# CTRL_MMR0_CFG0 register map
Vendor: Texas Instruments
Registers are 32-bit, read-write, reset 0x0 unless marked. A register's access mark holds for its fields unless they carry their own. Offsets are as the file gives them; [hi:lo] are bit positions; {n}, {i} and the like mark numbered series; 'fields as' and 'values as' point back to an identical list.

## CTRL_MMR0_CFG0 (part 5 of 9)
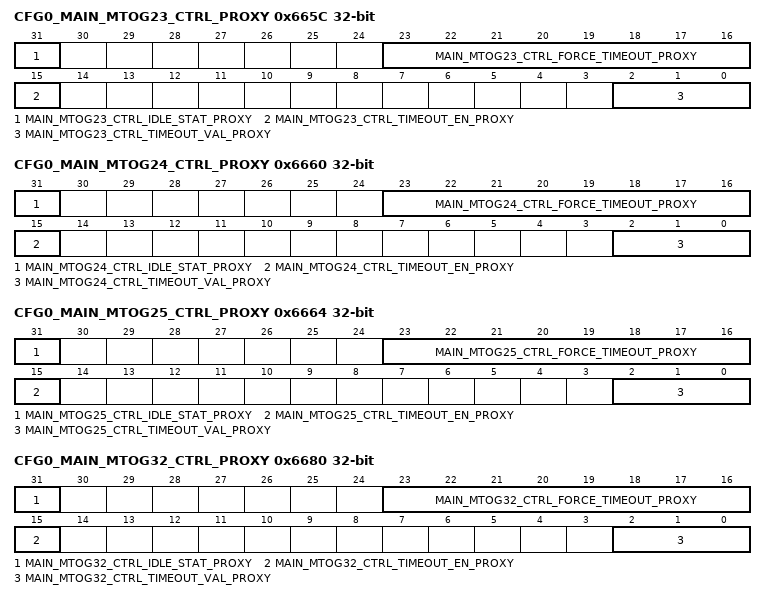
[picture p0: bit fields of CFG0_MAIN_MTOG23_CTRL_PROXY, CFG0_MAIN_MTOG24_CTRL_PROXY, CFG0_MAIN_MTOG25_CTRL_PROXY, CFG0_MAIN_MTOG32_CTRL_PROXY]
0x665C CFG0_MAIN_MTOG23_CTRL_PROXY access per field — Controls timeout operation of write transactions from the MAIN R5 Clstr1 Core 1 VBUSM Memory master port
  [31] MAIN_MTOG23_CTRL_IDLE_STAT_PROXY ro — Idle statusWhen high, indicates MTOG23 is idle.
  [23:16] MAIN_MTOG23_CTRL_FORCE_TIMEOUT_PROXY rw — Force TimeoutForces a flush of the interface transactions. This bitfield is only relevant if timeout_en=1. After forcing a timeout by writing the encoded value, the force_timeout and timeout_en bitfields must be cleared to clear the timeout before re-enabling the gasket. 8'h95 - Force a gasket timeoutAll others - Normal operation
  [15] MAIN_MTOG23_CTRL_TIMEOUT_EN_PROXY rw — Timeout Enable 1'b0 - Disable the gasket. Clear the interrupt and reset the counter 1'b1 - Enable the timeout gasket functions
  [2:0] MAIN_MTOG23_CTRL_TIMEOUT_VAL_PROXY rw — Gasket Timeout ValueSelects the number of clock cycles before the interface is considered to have timed out Field values (Others are reserved): 3'b000 - 1024 clock cycles 3'b001 - 4096 clock cycles 3'b010 - 16,384 clock cycles 3'b011 - 65,536 clock cycles 3'b100 - 262,144 clock cycles 3'b101 - 1,048,576 clock cycles 3'b110 - 2,097,152 clock cycles 3'b111 - 4,194,303 clock cycles
0x6660 CFG0_MAIN_MTOG24_CTRL_PROXY access per field — Controls timeout operation of real time transactions from High Speed IO masters
  [31] MAIN_MTOG24_CTRL_IDLE_STAT_PROXY ro — Idle statusWhen high, indicates MTOG24 is idle.
  [23:16] MAIN_MTOG24_CTRL_FORCE_TIMEOUT_PROXY rw — Force TimeoutForces a flush of the interface transactions. This bitfield is only relevant if timeout_en=1. After forcing a timeout by writing the encoded value, the force_timeout and timeout_en bitfields must be cleared to clear the timeout before re-enabling the gasket. 8'h95 - Force a gasket timeoutAll others - Normal operation
  [15] MAIN_MTOG24_CTRL_TIMEOUT_EN_PROXY rw — Timeout Enable 1'b0 - Disable the gasket. Clear the interrupt and reset the counter 1'b1 - Enable the timeout gasket functions
  [2:0] MAIN_MTOG24_CTRL_TIMEOUT_VAL_PROXY rw — Gasket Timeout ValueSelects the number of clock cycles before the interface is considered to have timed out Field values (Others are reserved): 3'b000 - 1024 clock cycles 3'b001 - 4096 clock cycles 3'b010 - 16,384 clock cycles 3'b011 - 65,536 clock cycles 3'b100 - 262,144 clock cycles 3'b101 - 1,048,576 clock cycles 3'b110 - 2,097,152 clock cycles 3'b111 - 4,194,303 clock cycles
0x6664 CFG0_MAIN_MTOG25_CTRL_PROXY access per field — Controls timeout operation of non-real time transactions from High Speed IO masters
  [31] MAIN_MTOG25_CTRL_IDLE_STAT_PROXY ro — Idle statusWhen high, indicates MTOG25 is idle.
  [23:16] MAIN_MTOG25_CTRL_FORCE_TIMEOUT_PROXY rw — Force TimeoutForces a flush of the interface transactions. This bitfield is only relevant if timeout_en=1. After forcing a timeout by writing the encoded value, the force_timeout and timeout_en bitfields must be cleared to clear the timeout before re-enabling the gasket. 8'h95 - Force a gasket timeoutAll others - Normal operation
  [15] MAIN_MTOG25_CTRL_TIMEOUT_EN_PROXY rw — Timeout Enable 1'b0 - Disable the gasket. Clear the interrupt and reset the counter 1'b1 - Enable the timeout gasket functions
  [2:0] MAIN_MTOG25_CTRL_TIMEOUT_VAL_PROXY rw — Gasket Timeout ValueSelects the number of clock cycles before the interface is considered to have timed out Field values (Others are reserved): 3'b000 - 1024 clock cycles 3'b001 - 4096 clock cycles 3'b010 - 16,384 clock cycles 3'b011 - 65,536 clock cycles 3'b100 - 262,144 clock cycles 3'b101 - 1,048,576 clock cycles 3'b110 - 2,097,152 clock cycles 3'b111 - 4,194,303 clock cycles
0x6680 CFG0_MAIN_MTOG32_CTRL_PROXY access per field — Controls timeout operation of Accelerator Cluster ASIL-B master accesses to MSMC (L2) SRAM
  [31] MAIN_MTOG32_CTRL_IDLE_STAT_PROXY ro — Idle statusWhen high, indicates MTOG32 is idle.
  [23:16] MAIN_MTOG32_CTRL_FORCE_TIMEOUT_PROXY rw — Force TimeoutForces a flush of the interface transactions. This bitfield is only relevant if timeout_en=1. After forcing a timeout by writing the encoded value, the force_timeout and timeout_en bitfields must be cleared to clear the timeout before re-enabling the gasket. 8'h95 - Force a gasket timeoutAll others - Normal operation
  [15] MAIN_MTOG32_CTRL_TIMEOUT_EN_PROXY rw — Timeout Enable 1'b0 - Disable the gasket. Clear the interrupt and reset the counter 1'b1 - Enable the timeout gasket functions
  [2:0] MAIN_MTOG32_CTRL_TIMEOUT_VAL_PROXY rw — Gasket Timeout ValueSelects the number of clock cycles before the interface is considered to have timed out Field values (Others are reserved): 3'b000 - 1024 clock cycles 3'b001 - 4096 clock cycles 3'b010 - 16,384 clock cycles 3'b011 - 65,536 clock cycles 3'b100 - 262,144 clock cycles 3'b101 - 1,048,576 clock cycles 3'b110 - 2,097,152 clock cycles 3'b111 - 4,194,303 clock cycles
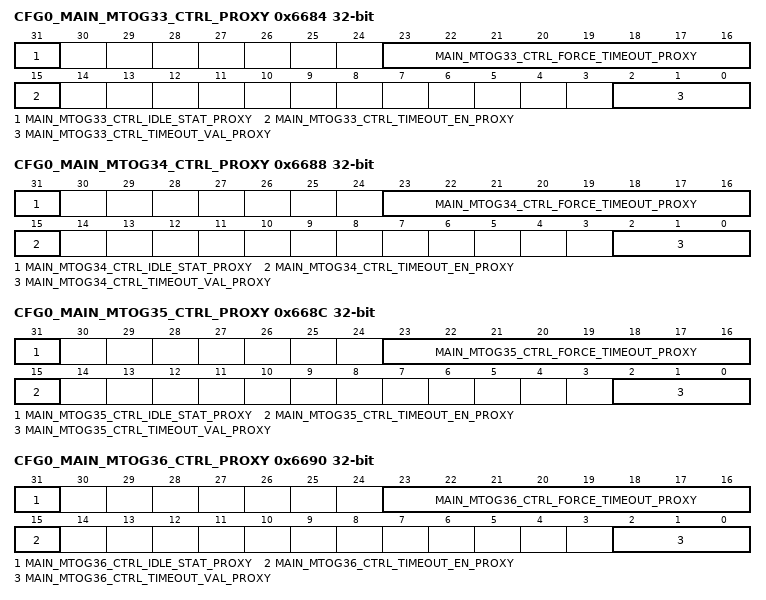
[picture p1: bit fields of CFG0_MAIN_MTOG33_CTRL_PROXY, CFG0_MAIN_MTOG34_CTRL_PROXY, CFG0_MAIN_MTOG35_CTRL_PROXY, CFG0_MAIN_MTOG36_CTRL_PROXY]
0x6684 CFG0_MAIN_MTOG33_CTRL_PROXY access per field — Controls timeout operation of Accelerator Cluster QueueManager master accesses to MSMC (L2) SRAM
  [31] MAIN_MTOG33_CTRL_IDLE_STAT_PROXY ro — Idle statusWhen high, indicates MTOG33 is idle.
  [23:16] MAIN_MTOG33_CTRL_FORCE_TIMEOUT_PROXY rw — Force TimeoutForces a flush of the interface transactions. This bitfield is only relevant if timeout_en=1. After forcing a timeout by writing the encoded value, the force_timeout and timeout_en bitfields must be cleared to clear the timeout before re-enabling the gasket. 8'h95 - Force a gasket timeoutAll others - Normal operation
  [15] MAIN_MTOG33_CTRL_TIMEOUT_EN_PROXY rw — Timeout Enable 1'b0 - Disable the gasket. Clear the interrupt and reset the counter 1'b1 - Enable the timeout gasket functions
  [2:0] MAIN_MTOG33_CTRL_TIMEOUT_VAL_PROXY rw — Gasket Timeout ValueSelects the number of clock cycles before the interface is considered to have timed out Field values (Others are reserved): 3'b000 - 1024 clock cycles 3'b001 - 4096 clock cycles 3'b010 - 16,384 clock cycles 3'b011 - 65,536 clock cycles 3'b100 - 262,144 clock cycles 3'b101 - 1,048,576 clock cycles 3'b110 - 2,097,152 clock cycles 3'b111 - 4,194,303 clock cycles
0x6688 CFG0_MAIN_MTOG34_CTRL_PROXY access per field — Controls timeout operation of Accelerator Cluster ASIL-B master accesses to DDR for OrderIDs 0-4
  [31] MAIN_MTOG34_CTRL_IDLE_STAT_PROXY ro — Idle statusWhen high, indicates MTOG34 is idle.
  [23:16] MAIN_MTOG34_CTRL_FORCE_TIMEOUT_PROXY rw — Force TimeoutForces a flush of the interface transactions. This bitfield is only relevant if timeout_en=1. After forcing a timeout by writing the encoded value, the force_timeout and timeout_en bitfields must be cleared to clear the timeout before re-enabling the gasket. 8'h95 - Force a gasket timeoutAll others - Normal operation
  [15] MAIN_MTOG34_CTRL_TIMEOUT_EN_PROXY rw — Timeout Enable 1'b0 - Disable the gasket. Clear the interrupt and reset the counter 1'b1 - Enable the timeout gasket functions
  [2:0] MAIN_MTOG34_CTRL_TIMEOUT_VAL_PROXY rw — Gasket Timeout ValueSelects the number of clock cycles before the interface is considered to have timed out Field values (Others are reserved): 3'b000 - 1024 clock cycles 3'b001 - 4096 clock cycles 3'b010 - 16,384 clock cycles 3'b011 - 65,536 clock cycles 3'b100 - 262,144 clock cycles 3'b101 - 1,048,576 clock cycles 3'b110 - 2,097,152 clock cycles 3'b111 - 4,194,303 clock cycles
0x668C CFG0_MAIN_MTOG35_CTRL_PROXY access per field — Controls timeout operation of Accelerator Cluster QueueManager master accesses to DDR fro OrderIDs 0-4
  [31] MAIN_MTOG35_CTRL_IDLE_STAT_PROXY ro — Idle statusWhen high, indicates MTOG35 is idle.
  [23:16] MAIN_MTOG35_CTRL_FORCE_TIMEOUT_PROXY rw — Force TimeoutForces a flush of the interface transactions. This bitfield is only relevant if timeout_en=1. After forcing a timeout by writing the encoded value, the force_timeout and timeout_en bitfields must be cleared to clear the timeout before re-enabling the gasket. 8'h95 - Force a gasket timeoutAll others - Normal operation
  [15] MAIN_MTOG35_CTRL_TIMEOUT_EN_PROXY rw — Timeout Enable 1'b0 - Disable the gasket. Clear the interrupt and reset the counter 1'b1 - Enable the timeout gasket functions
  [2:0] MAIN_MTOG35_CTRL_TIMEOUT_VAL_PROXY rw — Gasket Timeout ValueSelects the number of clock cycles before the interface is considered to have timed out Field values (Others are reserved): 3'b000 - 1024 clock cycles 3'b001 - 4096 clock cycles 3'b010 - 16,384 clock cycles 3'b011 - 65,536 clock cycles 3'b100 - 262,144 clock cycles 3'b101 - 1,048,576 clock cycles 3'b110 - 2,097,152 clock cycles 3'b111 - 4,194,303 clock cycles
0x6690 CFG0_MAIN_MTOG36_CTRL_PROXY access per field — Controls timeout operation of Accelerator Cluster ASIL-B master accesses to DDR for OrderIDs 5-9
  [31] MAIN_MTOG36_CTRL_IDLE_STAT_PROXY ro — Idle statusWhen high, indicates MTOG36 is idle.
  [23:16] MAIN_MTOG36_CTRL_FORCE_TIMEOUT_PROXY rw — Force TimeoutForces a flush of the interface transactions. This bitfield is only relevant if timeout_en=1. After forcing a timeout by writing the encoded value, the force_timeout and timeout_en bitfields must be cleared to clear the timeout before re-enabling the gasket. 8'h95 - Force a gasket timeoutAll others - Normal operation
  [15] MAIN_MTOG36_CTRL_TIMEOUT_EN_PROXY rw — Timeout Enable 1'b0 - Disable the gasket. Clear the interrupt and reset the counter 1'b1 - Enable the timeout gasket functions
  [2:0] MAIN_MTOG36_CTRL_TIMEOUT_VAL_PROXY rw — Gasket Timeout ValueSelects the number of clock cycles before the interface is considered to have timed out Field values (Others are reserved): 3'b000 - 1024 clock cycles 3'b001 - 4096 clock cycles 3'b010 - 16,384 clock cycles 3'b011 - 65,536 clock cycles 3'b100 - 262,144 clock cycles 3'b101 - 1,048,576 clock cycles 3'b110 - 2,097,152 clock cycles 3'b111 - 4,194,303 clock cycles
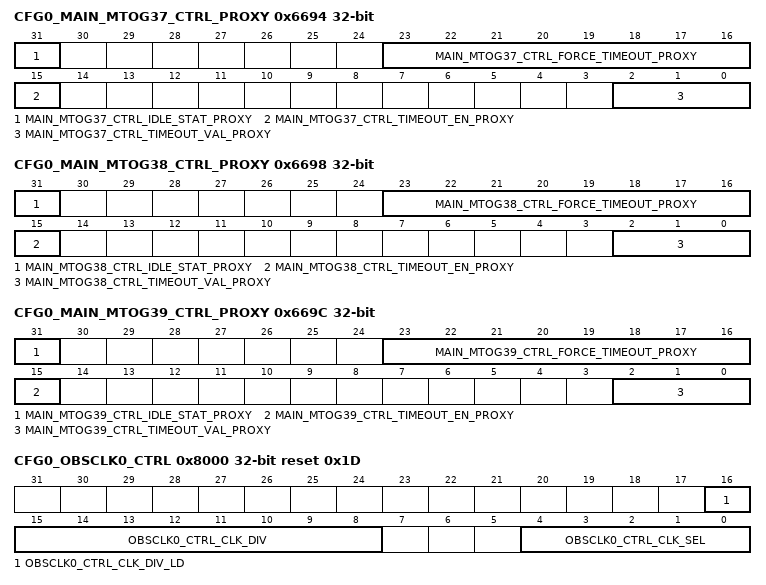
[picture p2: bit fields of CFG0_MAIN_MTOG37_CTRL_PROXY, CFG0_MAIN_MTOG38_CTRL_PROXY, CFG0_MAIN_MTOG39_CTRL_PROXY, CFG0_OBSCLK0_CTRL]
0x6694 CFG0_MAIN_MTOG37_CTRL_PROXY access per field — Controls timeout operation of Accelerator Cluster QueueManager master accesses to DDR for OrderIDs 5-9
  [31] MAIN_MTOG37_CTRL_IDLE_STAT_PROXY ro — Idle statusWhen high, indicates MTOG37 is idle.
  [23:16] MAIN_MTOG37_CTRL_FORCE_TIMEOUT_PROXY rw — Force TimeoutForces a flush of the interface transactions. This bitfield is only relevant if timeout_en=1. After forcing a timeout by writing the encoded value, the force_timeout and timeout_en bitfields must be cleared to clear the timeout before re-enabling the gasket. 8'h95 - Force a gasket timeoutAll others - Normal operation
  [15] MAIN_MTOG37_CTRL_TIMEOUT_EN_PROXY rw — Timeout Enable 1'b0 - Disable the gasket. Clear the interrupt and reset the counter 1'b1 - Enable the timeout gasket functions
  [2:0] MAIN_MTOG37_CTRL_TIMEOUT_VAL_PROXY rw — Gasket Timeout ValueSelects the number of clock cycles before the interface is considered to have timed out Field values (Others are reserved): 3'b000 - 1024 clock cycles 3'b001 - 4096 clock cycles 3'b010 - 16,384 clock cycles 3'b011 - 65,536 clock cycles 3'b100 - 262,144 clock cycles 3'b101 - 1,048,576 clock cycles 3'b110 - 2,097,152 clock cycles 3'b111 - 4,194,303 clock cycles
0x6698 CFG0_MAIN_MTOG38_CTRL_PROXY access per field — Controls timeout operation of Accelerator Cluster ASIL-B master accesses to DDR for OrderIDs 10-15
  [31] MAIN_MTOG38_CTRL_IDLE_STAT_PROXY ro — Idle statusWhen high, indicates MTOG38 is idle.
  [23:16] MAIN_MTOG38_CTRL_FORCE_TIMEOUT_PROXY rw — Force TimeoutForces a flush of the interface transactions. This bitfield is only relevant if timeout_en=1. After forcing a timeout by writing the encoded value, the force_timeout and timeout_en bitfields must be cleared to clear the timeout before re-enabling the gasket. 8'h95 - Force a gasket timeoutAll others - Normal operation
  [15] MAIN_MTOG38_CTRL_TIMEOUT_EN_PROXY rw — Timeout Enable 1'b0 - Disable the gasket. Clear the interrupt and reset the counter 1'b1 - Enable the timeout gasket functions
  [2:0] MAIN_MTOG38_CTRL_TIMEOUT_VAL_PROXY rw — Gasket Timeout ValueSelects the number of clock cycles before the interface is considered to have timed out Field values (Others are reserved): 3'b000 - 1024 clock cycles 3'b001 - 4096 clock cycles 3'b010 - 16,384 clock cycles 3'b011 - 65,536 clock cycles 3'b100 - 262,144 clock cycles 3'b101 - 1,048,576 clock cycles 3'b110 - 2,097,152 clock cycles 3'b111 - 4,194,303 clock cycles
0x669C CFG0_MAIN_MTOG39_CTRL_PROXY access per field — Controls timeout operation of Accelerator Cluster QueueManager master accesses to DDR for OrderIDs 10-15
  [31] MAIN_MTOG39_CTRL_IDLE_STAT_PROXY ro — Idle statusWhen high, indicates MTOG39 is idle.
  [23:16] MAIN_MTOG39_CTRL_FORCE_TIMEOUT_PROXY rw — Force TimeoutForces a flush of the interface transactions. This bitfield is only relevant if timeout_en=1. After forcing a timeout by writing the encoded value, the force_timeout and timeout_en bitfields must be cleared to clear the timeout before re-enabling the gasket. 8'h95 - Force a gasket timeoutAll others - Normal operation
  [15] MAIN_MTOG39_CTRL_TIMEOUT_EN_PROXY rw — Timeout Enable 1'b0 - Disable the gasket. Clear the interrupt and reset the counter 1'b1 - Enable the timeout gasket functions
  [2:0] MAIN_MTOG39_CTRL_TIMEOUT_VAL_PROXY rw — Gasket Timeout ValueSelects the number of clock cycles before the interface is considered to have timed out Field values (Others are reserved): 3'b000 - 1024 clock cycles 3'b001 - 4096 clock cycles 3'b010 - 16,384 clock cycles 3'b011 - 65,536 clock cycles 3'b100 - 262,144 clock cycles 3'b101 - 1,048,576 clock cycles 3'b110 - 2,097,152 clock cycles 3'b111 - 4,194,303 clock cycles
0x66C0 CFG0_CC_FLUSH_CTRL0_PROXY — This register is used isolate the MSMC ARM Corepac 0 interface from other MSMC transactions in case of an ARM Corepac access hang. This allows continuation of other MSMC traffic (e.g. R5 processors) without interference. After asserting this flush, the ARM Corepac can be forced through a power cycle sequence to clear the hang condition. (See Compute Cluster Spec for sequence details.)
  [7:0] CC_FLUSH_CTRL0_FLUSH_PROXY — Flush ARM / MSMC Interface TransactionsForces a flush of the A72 MSMC interface. This bit field can be used to force a flush of A72 transactions to the MSMC and force an auto response of any MSMC snoop requests to the A72. An encoded bit value is used to prevent accidental activation of the flush signal. 8'h95 - Force a flush (FFI Mode) condition (flush signal driven high)All others - Normal operation (flush signal driven low)
0x66D0 CFG0_CC_FLUSH_CTRL4_PROXY — This register is used isolate the MSMC C7x Corepac 4 (C71x_0) interface from other MSMC transactions in case of an C7x Corepac access hang. This allows continuation of other MSMC traffic (e.g. R5 processors) without interference. After asserting this flush, the C7x Corepac can be forced through a power cycle sequence to clear the hang condition. (See Compute Cluster Spec for sequence details.)
  [7:0] CC_FLUSH_CTRL4_FLUSH_PROXY — Flush C7x / MSMC Interface TransactionsForces a flush of the C7x MSMC interface. This bit field can be used to force a flush of C7x transactions to the MSMC and force an auto response of any MSMC snoop requests to the C7x. An encoded bit value is used to prevent accidental activation of the flush signal. 8'h95 - Force a flush (FFI Mode) condition (flush signal driven high)All others - Normal operation (flush signal driven low)
0x66D4 CFG0_CC_FLUSH_CTRL5_PROXY — This register is used isolate the MSMC C7x Corepac 5 (C71x_1) interface from other MSMC transactions in case of an C7x Corepac access hang. This allows continuation of other MSMC traffic (e.g. R5 processors) without interference. After asserting this flush, the C7x Corepac can be forced through a power cycle sequence to clear the hang condition. (See Compute Cluster Spec for sequence details.)
  [7:0] CC_FLUSH_CTRL5_FLUSH_PROXY — Flush C7x / MSMC Interface TransactionsForces a flush of the C7x MSMC interface. This bit field can be used to force a flush of C7x transactions to the MSMC and force an auto response of any MSMC snoop requests to the C7x. An encoded bit value is used to prevent accidental activation of the flush signal. 8'h95 - Force a flush (FFI Mode) condition (flush signal driven high)All others - Normal operation (flush signal driven low)
0x66E0 CFG0_CC_FLUSH_CTRL8_PROXY — This register is used isolate the MSMC DRU 0 Interfaces from other MSMC transactions in case of a DRU 0 access hang. This allows continuation of other MSMC traffic (e.g. R5 processors) without interference. After asserting this flush, the DRU can be forced through a power cycle sequence to clear the hang condition. (See Compute Cluster Spec for sequence details.)
  [7:0] CC_FLUSH_CTRL8_FLUSH_PROXY — Flush DRU 0 / MSMC Interface TransactionsForces a flush of the DRU 0 MSMC interface. This bit field can be used to force a flush of DRU 0 transactions to the MSMC and force an auto response of any MSMC snoop requests to the DRU. An encoded bit value is used to prevent accidental activation of the flush signal. 8'h95 - Force a flush (FFI Mode) condition (flush signal driven high)All others - Normal operation (flush signal driven low)
{0x7100+4i} CFG0_CLAIMREG_P1_R{i} (i=0..14)
  [31:0] CLAIMREG_P1_R{i} — Claim bits for Partition 1
0x8000 CFG0_OBSCLK0_CTRL reset 0x1D — This register controls which internal clock is made observable on the OBSCLK[2:0] output pins
  [16] OBSCLK0_CTRL_CLK_DIV_LD — Load the output divider valueWriting 1 to this bit will generate a load pulse to load the OBSCLK0 divider value. This bit can be cleared but must not be set in the same write cycle in which the clk_div value is changed.
  [15:8] OBSCLK0_CTRL_CLK_DIV — OBSCLK0 output dividerDivides the selected clock by clkdiv+1 for output to the OBSCLK[2:0] pins. Supports divide by 1 to 256 (default to 1). To load the new divider value the clk_div_ld bit must be cleared and then set to 1.
  [4:0] OBSCLK0_CTRL_CLK_SEL — OBSCLK0 clock source selection.Selects the source of the clock to be divided by the OBSCLK0 divider and output on the OBSCLK[2:0] pins. Field values (Others are reserved): 5'b00000 - MAIN_PLL0_HSDIV0_CLKOUT 5'b00001 - MAIN_PLL1_HSDIV0_CLKOUT 5'b00010 - MAIN_PLL2_HSDIV1_CLKOUT 5'b00011 - MAIN_PLL3_HSDIV0_CLKOUT 5'b00100 - MAIN_PLL4_HSDIV0_CLKOUT 5'b00101 - MAIN_PLL5_HSDIV0_CLKOUT 5'b00110 - MAIN_PLL6_HSDIV0_CLKOUT 5'b00111 - MAIN_PLL26_HSDIV0_CLKOUT 5'b01000 - 0 5'b01001 - 0 5'b01010 - 0 5'b01011 - 0 5'b01100 - MAIN_PLL12_HSDIV0_CLKOUT 5'b01101 - OBSCLK1 OUT 5'b01110 - MAIN_PLL14_HSDIV0_CLKOUT 5'b01111 - 0 5'b10000 - MAIN_PLL16_HSDIV0_CLKOUT 5'b10001 - MAIN_PLL17_HSDIV0_CLKOUT 5'b10010 - 0 5'b10011 - MAIN_PLL19_HSDIV0_CLKOUT 5'b10100 - 0 5'b10101 - 0 5'b10110 - 0 5'b10111 - 0 5'b11000 - 0 5'b11001 - MAIN_PLL25_HSDIV0_CLKOUT 5'b11010 - CPTS_GENF3 5'b11011 - CLK_12M_RC 5'b11100 - LFXOSC_CLKOUT 5'b11101 - PLLCTRL_OBSCLK 5'b11110 - HFOSC1_CLKOUT 5'b11111 - HFOSC0_CLKOUT
0x8004 CFG0_OBSCLK1_CTRL — This register controls which internal clock is made observable on the OBSCLK1_OUT internal clock signal
  [1:0] OBSCLK1_CTRL_CLK_SEL — OBSCLK1_OUT signal output clock source selection Field values (Others are reserved): 2'b00 - MAIN_PLL7_HSDIV0_CLKOUT / DIV4 2'b01 - MAIN_PLL8_HSDIV0_CLKOUT / DIV8 2'b10 - 0 2'b11 - 0
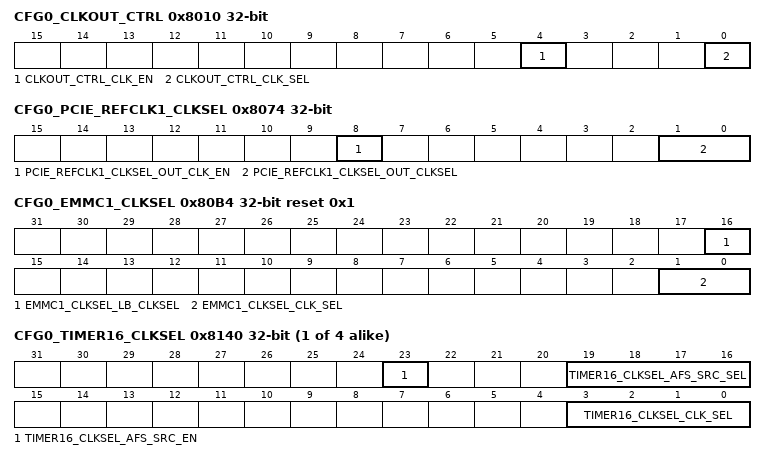
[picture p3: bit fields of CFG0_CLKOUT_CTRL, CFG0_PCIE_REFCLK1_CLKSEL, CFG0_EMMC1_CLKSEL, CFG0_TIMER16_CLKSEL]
0x8010 CFG0_CLKOUT_CTRL — Enables and selects clock source of CPSW CLKOUT pin
  [4] CLKOUT_CTRL_CLK_EN — When set, enables CLKOUT output
  [0] CLKOUT_CTRL_CLK_SEL — Selects CLKOUT clock source 1'b0 - RGMII_MHZ_50_CLK (50 MHz) 1'b1 -RGMII_MHZ_50_CLK_DIV2 (25 MHz)
0x8030 CFG0_GTC_CLKSEL — Selects the timebase clock source for the Global Timebase Counter
  [3:0] GTC_CLKSEL_CLK_SEL — Selects the GTC timebase clock source Field values (Others are reserved): 4'b0000 - MAIN_PLL3_HSDIV1_CLKOUT 4'b0001 - MAIN_PLL0_HSDIV6_CLKOUT 4'b0010 - MCU_CPTS_REF_CLK (pin) 4'b0011 - CPTS_RFT_CLK (pin) 4'b0100 - MCU_EXT_REFCLK0 (pin) 4'b0101 - EXT_REFCLK1 (pin) 4'b0110 - SERDES0_IP2_LN0_TXMCLK 4'b0111 - SERDES0_IP2_LN1_TXMCLK 4'b1000 - SERDES0_IP2_LN2_TXMCLK 4'b1001 - SERDES0_IP2_LN3_TXMCLK 4'b1010 - 0 4'b1011 - SERDES1_IP2_LN1_TXMCLK 4'b1100 - 0 4'b1101 - 0 4'b1110 - MCU_PLL2_HSDIV1_CLKOUT 4'b1111 - MAIN_SYSCLK0
0x803C CFG0_EFUSE_CLKSEL — Selects the functional clock source for the MAIN domain eFuse Controller
  [0] EFUSE_CLKSEL_CLK_SEL — Selects the clock source Field values (Others are reserved): 1'b0 - HFOSC0_CLKOUT 1'b1 - MAIN_SYSCLK0 / 4
0x8074 CFG0_PCIE_REFCLK1_CLKSEL — PCIE_REFCLK1 P/N are driven by ACSPCIE0 PAD 0
  [8] PCIE_REFCLK1_CLKSEL_OUT_CLK_EN — Enables the output of the ACSPCIE buffer to drive the PCIE1 REFCLK P/N pins
  [1:0] PCIE_REFCLK1_CLKSEL_OUT_CLKSEL — Selects the PCIE1 REFCLK output clock source.Controls the ACSPCIE0 buffer PAD0 clock mux. Field values (Others are reserved): 2'b00 - SERDES0_REF_DER_OUT_CLK 2'b01 - MAIN_PLL2_HSDIV4_CLKOUT 2'b10 - SERDES0_REF_OUT_CLK 2'b11 - 0
0x8084 CFG0_PCIE1_CLKSEL — Selects PCIe1 functional clock sources
  [3:0] PCIE1_CLKSEL_CPTS_CLKSEL — Selects the clock source for the PCIE1 Common Platform Time Stamp module Field values (Others are reserved): 4'b0000 - MAIN_PLL3_HSDIV1_CLKOUT 4'b0001 - MAIN_PLL0_HSDIV6_CLKOUT 4'b0010 - MCU_CPTS_REF_CLK (pin) 4'b0011 - CPTS_RFT_CLK (pin) 4'b0100 - MCU_EXT_REFCLK0 (pin) 4'b0101 - EXT_REFCLK1 (pin) 4'b0110 - SERDES0_IP2_LN0_TXMCLK 4'b0111 - SERDES0_IP2_LN1_TXMCLK 4'b1000 - SERDES0_IP2_LN2_TXMCLK 4'b1001 - SERDES0_IP2_LN3_TXMCLK 4'b1010 - 0 4'b1011 - 0 4'b1100 - 0 4'b1101 - 0 4'b1110 - MCU_PLL2_HSDIV1_CLKOUT 4'b1111 - MAIN_SYSCLK0
0x8094 CFG0_CPSW2_CLKSEL — Selects the 2 port CP Switch clock sources
  [3:0] CPSW2_CLKSEL_CPTS_CLKSEL — Selects the clock source for the CPSW2G Ethernet switch Common Platform Time Stamp module Field values (Others are reserved): 4'b0000 - MAIN_PLL3_HSDIV1_CLKOUT 4'b0001 - MAIN_PLL0_HSDIV6_CLKOUT 4'b0010 - MCU_CPTS_REF_CLK (pin) 4'b0011 - CPTS_RFT_CLK (pin) 4'b0100 - MCU_EXT_REFCLK0 (pin) 4'b0101 - EXT_REFCLK1 (pin) 4'b0110 - SERDES0_IP2_LN0_TXMCLK 4'b0111 - SERDES0_IP2_LN1_TXMCLK 4'b1000 - SERDES0_IP2_LN2_TXMCLK 4'b1001 - SERDES0_IP2_LN3_TXMCLK 4'b1010 - 0 4'b1011 - 0 4'b1100 - 0 4'b1101 - 0 4'b1110 - MCU_PLL2_HSDIV1_CLKOUT 4'b1111 - MAIN_SYSCLK0
0x8098 CFG0_NAVSS_CLKSEL — Selects the clock source for the NavSS Subsystem
  [3:0] NAVSS_CLKSEL_CPTS_CLKSEL — Selects the clock source for the SoC] Common Platform Time Stamp module located within the Nav Subsystem Field values (Others are reserved): 4'b0000 - MAIN_PLL3_HSDIV1_CLKOUT 4'b0001 - MAIN_PLL0_HSDIV6_CLKOUT 4'b0010 - MCU_CPTS_REF_CLK (pin) 4'b0011 - CPTS_RFT_CLK (pin) 4'b0100 - MCU_EXT_REFCLK0 (pin) 4'b0101 - EXT_REFCLK1 (pin) 4'b0110 - SERDES0_IP2_LN0_TXMCLK 4'b0111 - SERDES0_IP2_LN1_TXMCLK 4'b1000 - SERDES0_IP2_LN2_TXMCLK 4'b1001 - SERDES0_IP2_LN3_TXMCLK 4'b1010 - 0 4'b1011 - 0 4'b1100 - 0 4'b1101 - 0 4'b1110 - MCU_PLL2_HSDIV1_CLKOUT 4'b1111 - MAIN_SYSCLK0
0x80B0 CFG0_EMMC0_CLKSEL — Selects the functional clock source for 8-bit eMMC0
  [1:0] EMMC0_CLKSEL_CLK_SEL — eMMC XIN_CLK selection 2'b00 - MAIN_PLL0_HSDIV2_CLKOUT 2'b01 - MAIN_PLL1_HSDIV2_CLKOUT 2'b10 - MAIN_PLL2_HSDIV2_CLKOUT 2'b11 - MAIN_PLL3_HSDIV2_CLKOUT
0x80B4 CFG0_EMMC1_CLKSEL reset 0x1 — Selects the functional clock source for 4-bit eMMC1
  [16] EMMC1_CLKSEL_LB_CLKSEL — eMMC Loopback clock selection 1'b0 - Loopback clock from MMC1_CLKLB pad 1'b1 - Loopback clock from MMC1_CLK pin
  [1:0] EMMC1_CLKSEL_CLK_SEL — eMMC XIN_CLK selection 2'b00 - MAIN_PLL0_HSDIV2_CLKOUT 2'b01 - MAIN_PLL1_HSDIV2_CLKOUT 2'b10 - MAIN_PLL2_HSDIV2_CLKOUT 2'b11 - MAIN_PLL3_HSDIV2_CLKOUT
0x80D0 CFG0_GPMC_CLKSEL — Selects the bus and functional clock source for the GPMC module. This allows the GPMC to run asynchronously to the bus fabric in order to optimize parallel port performance.
  [1:0] GPMC_CLKSEL_CLK_SEL — Selects the GPMC clock source 2'b00 - MAIN_PLL0_HSDIV3_CLKOUT 2'b01 - MAIN_PLL2_HSDIV1_CLKOUT / 6 2'b10 - MAIN_PLL2_HSDIV1_CLKOUT / 4 2'b11 - MAIN_SYSCLK0 / 4
0x80E0 CFG0_USB0_CLKSEL — Selects the functional clock sources for USB0
  [0] USB0_CLKSEL_REFCLK_SEL — Selects the clock source for the USB0 ref_clk. 1'b0 - Use HFOSC0_CLKOUT 1'b1 - Use HFOSC1_CLKOUT
0x80F0 CFG0_VPAC_CLKSEL — Selects the functional clock sources for VPAC0
  [0] VPAC_CLKSEL_CLK_SEL — VPAC clock selection 1'b0 - MAIN_PLL25_HSDIV1_CLKOUT 1'b1 - MAIN_PLL2_HSDIV1_CLKOUT
{0x8100+4i} CFG0_TIMER{i}_CLKSEL (i=0..15) — Timer{i} functional clock selection control
  [3:0] TIMER{i}_CLKSEL_CLK_SEL — Timer functional clock input select mux control (Reserved values default to HFOSC1_CLK) Field values (Others are reserved): 4'b0000 - HFOSC0_CLKOUT 4'b0001 - HFOSC1_CLKOUT 4'b0010 - MAIN_PLL0_HSDIV1_CLKOUT 4'b0011 - CLK_12M_RC 4'b0100 - MAIN_PLL3_HSDIV3_CLKOUT 4'b0101 - MCU_EXT_REFCLK0 (pin) 4'b0110 - EXT_REFCLK1 (pin) 4'b0111 - LFXOSC_CLKOUT 4'b1000 - CPTS_RFT_CLK (pin) 4'b1001 - MAIN_PLL1_HSDIV3_CLKOUT 4'b1010 - MAIN_PLL2_HSDIV6_CLKOUT 4'b1011 - MAIN_PLL4_HSDIV2_CLKOUT 4'b1100 - CPTS_GENF2 4'b1101 - CPTS_GENF3 4'b1110 - CPSW2G_CPTS_GENF0 4'b1111 - 0
{0x8100+4i} CFG0_TIMER{i}_CLKSEL (i=16..19) — Timer{i} functional clock selection control
  [23] TIMER{i}_CLKSEL_AFS_SRC_EN — Enable AFS source mux output as the Timer clock source. Note that for TIMER17 and TIMER19 this selection will be overridden if cascade_en in the associated TIMERn_CTRL register is set. 0 - Use functional clock selected by clk_sel value 1 - Use AFS input selected by afs_src_sel value
  [19:16] TIMER{i}_CLKSEL_AFS_SRC_SEL — Selects the ASFR/AFSX input to use as a timer clock when afs_src_en is set. Field values (Others are reserved): 4'b0000 - McASP0_AFSR 4'b0001 - McASP0_AFSX 4'b0010 - McASP1_AFSR 4'b0011 - McASP1_AFSX 4'b0100 - McASP2_AFSR 4'b0101 - McASP2_AFSX 4'b0110 - McASP3_AFSR 4'b0111 - McASP3_AFSX 4'b1000 - McASP4_AFSR 4'b1001 - McASP4_AFSX 4'b1010 - 0 4'b1011 - 0 4'b1100 - 0 4'b1101 - 0 4'b1110 - 0 4'b1111 - 0
  [3:0] TIMER{i}_CLKSEL_CLK_SEL — Timer functional clock input select mux control (Reserved values default to HFOSC1_CLK) Field values (Others are reserved): 4'b0000 - HFOSC0_CLKOUT 4'b0001 - HFOSC1_CLKOUT 4'b0010 - MAIN_PLL0_HSDIV1_CLKOUT 4'b0011 - CLK_12M_RC 4'b0100 - MAIN_PLL3_HSDIV3_CLKOUT 4'b0101 - MCU_EXT_REFCLK0 (pin) 4'b0110 - EXT_REFCLK1 (pin) 4'b0111 - LFXOSC_CLKOUT 4'b1000 - CPTS_RFT_CLK (pin) 4'b1001 - MAIN_PLL1_HSDIV3_CLKOUT 4'b1010 - MAIN_PLL2_HSDIV6_CLKOUT 4'b1011 - MAIN_PLL4_HSDIV2_CLKOUT 4'b1100 - CPTS_GENF2 4'b1101 - CPTS_GENF3 4'b1110 - CPSW2G_CPTS_GENF0 4'b1111 - 0
{0x8190+4i} CFG0_SPI{i}_CLKSEL (i=0..3) — SPI{i} clock control
  [16] SPI{i}_CLKSEL_MSTR_LB_CLKSEL — Master mode receive capture clock loopback selection 1'b0 - Internal clock loopback 1'b1 - Loopback from pad
{0x8190+4i} CFG0_SPI{i}_CLKSEL (i=5..7) — SPI{i} clock control
  fields as CFG0_SPI0_CLKSEL
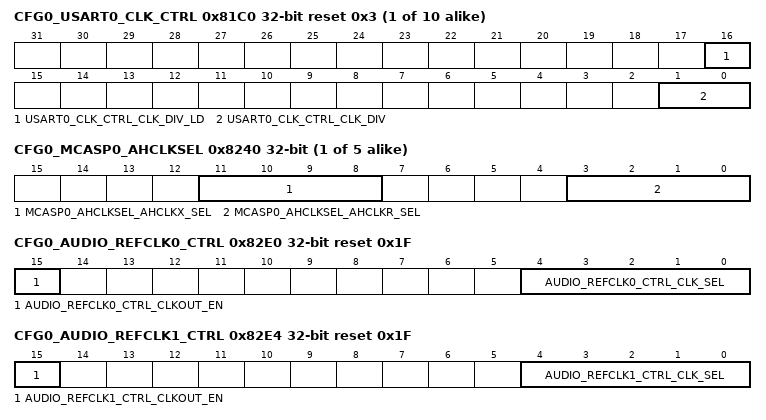
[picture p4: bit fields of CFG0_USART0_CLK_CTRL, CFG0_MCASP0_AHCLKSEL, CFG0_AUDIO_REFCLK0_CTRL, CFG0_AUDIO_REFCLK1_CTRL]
{0x81C0+4i} CFG0_USART{i}_CLK_CTRL reset 0x3 (i=0..9) — Selects the clock divider of the USART{i} functional clock
  [16] USART{i}_CLK_CTRL_CLK_DIV_LD — Load the output divider valueWriting 1 to this bit will generate a load pulse to load the USART{i} clock programmable divider value. This bit can be cleared but must not be set in the same write cycle in which the clk_div value is changed.
  [1:0] USART{i}_CLK_CTRL_CLK_DIV — Selects the clock divider value. Supports divide values of 1 to 4 Default is /4. To load the new divider value the clk_div_ld bit must be cleared and then set to 1. Field values (Others are reserved): 2'b00 - Divide by 1 2'b01 - Divide by 2 2'b10 - Divide by 3 2'b11 - Divide by 4
{0x8200+4i} CFG0_MCASP{i}_CLKSEL (i=0..4) — Selects the functional clock source for McASP{i}
  [2:0] MCASP{i}_CLKSEL_AUXCLK_SEL — Selects the McASP{i} auxclk clock source Reserved values default to HFOSC1_CLK Field values (Others are reserved): 3'b000 - MAIN_PLL4_HSDIV0_CLKOUT 3'b001 - MAIN_PLL2_HSDIV2_CLKOUT 3'b010 - 0 3'b011 - 0 3'b100 - ATCLK0 3'b101 - ATCLK1 3'b110 - ATCLK2 3'b111 - ATCLK3
{0x8240+4i} CFG0_MCASP{i}_AHCLKSEL (i=0..4) — Selects the AHCLKX and AHCLKR clock source for McASP{i}
  [11:8] MCASP{i}_AHCLKSEL_AHCLKX_SEL — Selects the AHCLKX input source for McASP{i} Field values (Others are reserved): 4'b0000 - HFOSC1_CLKOUT 4'b0001 - HFOSC0_CLKOUT 4'b0010 - AUDIO_EXT_REFCLK0_IN 4'b0011 - AUDIO_EXT_REFCLK1_IN 4'b0100 - 0 4'b0101 - 0 4'b0110 - 0 4'b0111 - 0 4'b1000 - ATCLK0 4'b1001 - ATCLK1 4'b1010 - ATCLK2 4'b1011 - ATCLK3
  [3:0] MCASP{i}_AHCLKSEL_AHCLKR_SEL — Selects the AHCLKR input source for McASP{i} Field values (Others are reserved): 4'b0000 - HFOSC1_CLKOUT 4'b0001 - HFOSC0_CLKOUT 4'b0010 - AUDIO_EXT_REFCLK0_IN 4'b0011 - AUDIO_EXT_REFCLK1_IN 4'b0100 - 0 4'b0101 - 0 4'b0110 - 0 4'b0111 - 0 4'b1000 - ATCLK0 4'b1001 - ATCLK1 4'b1010 - ATCLK2 4'b1011 - ATCLK3 4'b1100 - 0 4'b1101 - 0 4'b1110 - 0 4'b1111 - 0
{0x82A0+4i} CFG0_ATL_BWS{i}_SEL (i=0..3) — Selects the source of ATL Baseband Word Select {i}
  [4:0] ATL_BWS{i}_SEL_WD_SEL — BWS source signal Field values (Others are reserved): 5'b00000 - McASP0 AFSR Pin Input 5'b00001 - McASP1 AFSR Pin Input 5'b00010 - McASP2 AFSR Pin Input 5'b00011 - McASP3 AFSR Pin Input 5'b00100 - McASP4 AFSR Pin Input 5'b00101 - 0 5'b00110 - 0 5'b00111 - 0 5'b01000 - 0 5'b01001 - 0 5'b01010 - 0 5'b01011 - 0 5'b01100 - McASP0 AFSX Pin Input 5'b01101 - McASP1 AFSX Pin Input 5'b01110 - McASP2 AFSX Pin Input 5'b01111 - McASP3 AFSX Pin Input 5'b10000 - McASP4 AFSX Pin Input 5'b10001 - 0 5'b10010 - 0 5'b10011 - 0 5'b10100 - 0 5'b10101 - 0 5'b10110 - 0 5'b10111 - 0 5'b11000 - AUDIO_EXT_REFCLK0 Pin input 5'b11001 - AUDIO_EXT_REFCLK1 Pin input 5'b11010 - 0 5'b11011 - 0
{0x82B0+4i} CFG0_ATL_AWS{i}_SEL (i=0..3) — Selects the source of ATL Audio Word Select {i}
  [4:0] ATL_AWS{i}_SEL_WD_SEL — AWS source signal Field values (Others are reserved): 5'b00000 - McASP0 AFSX Pin Input 5'b00001 - McASP1 AFSX Pin Input 5'b00010 - McASP2 AFSX Pin Input 5'b00011 - McASP3 AFSX Pin Input 5'b00100 - McASP4 AFSX Pin Input 5'b00101 - 0 5'b00110 - 0 5'b00111 - 0 5'b01000 - 0 5'b01001 - 0 5'b01010 - 0 5'b01011 - 0 5'b01100 - McASP0 AFSX Pin Input 5'b01101 - McASP1 AFSX Pin Input 5'b01110 - McASP2 AFSX Pin Input 5'b01111 - McASP3 AFSX Pin Input 5'b10000 - McASP4 AFSX Pin Input 5'b10001 - 0 5'b10010 - 0 5'b10011 - 0 5'b10100 - 0 5'b10101 - 0 5'b10110 - 0 5'b10111 - 0 5'b11000 - AUDIO_EXT_REFCLK0 Pin input 5'b11001 - AUDIO_EXT_REFCLK1 Pin input 5'b11010 - 0 5'b11011 - 0 5'b11100 - 0 5'b11101 - 0
0x82C0 CFG0_ATL_CLKSEL — Selects the source of the ATL PCLK
  [3:0] ATL_CLKSEL_PCLK_SEL — Selects the PCLK clock source Field values (Others are reserved): 3'b000 - MAIN_PLL4_HSDIV1_CLKOUT 3'b001 - MAIN_PLL2_HSDIV2_CLKOUT 3'b010 - 0 3'b011 - 0 3'b100 - MAIN_PLL0_HSDIV7_CLKOUT 3'b101 - MCU_EXT_REFCLK0 (pin) 3'b110 - EXT_REFCLK1 (pin) 3'b111 - 0
0x82E0 CFG0_AUDIO_REFCLK0_CTRL reset 0x1F — Selects the clock source for the AUDIO_EXT_REFCLK0 output
  [15] AUDIO_REFCLK0_CTRL_CLKOUT_EN — AUDIO_REFCLK 0 output enableThis bit is inverted to drive the active low output buffer enable 0 - AUDIO_EXT_REFCLK0 pin is configured as an input 1 - AUDIO_EXT_REFCLK0 pin is configured as an output
  [4:0] AUDIO_REFCLK0_CTRL_CLK_SEL — Clock source (default selects a tie-off of 0 for no output) Field values (Others are reserved): 5'b00000 - MCASP0 AHCLKR Output 5'b00001 - MCASP1 AHCLKR Output 5'b00010 - MCASP2 AHCLKR Output 5'b00011 - MCASP3 AHCLKR Output 5'b00100 - MCASP4 AHCLKR Output 5'b01100 - MCASP0 AHCLKX Output 5'b01101 - MCASP1 AHCLKX Output 5'b01110 - MCASP2 AHCLKX Output 5'b01111 - MCASP3 AHCLKX Output 5'b10000 - MCASP4 AHCLKX Output 5'b11000 - ATCLK0 5'b11001 - ATCLK1 5'b11010 - ATCLK2 5'b11011 - ATCLK3 5'b11100 - MAIN_PLL4_HSDIV2_CLKOUT 5'b11101 - 0 5'b11110 - 0 5'b11111 - 0
0x82E4 CFG0_AUDIO_REFCLK1_CTRL reset 0x1F — Selects the clock source for the AUDIO_EXT_REFCLK1 output
  [15] AUDIO_REFCLK1_CTRL_CLKOUT_EN — AUDIO_REFCLK 1 output enableThis bit is inverted to drive the active low output buffer enable 0 - AUDIO_EXT_REFCLK1 pin is configured as an input 1 - AUDIO_EXT_REFCLK1 pin is configured as an output
  [4:0] AUDIO_REFCLK1_CTRL_CLK_SEL — Clock source (default selects a tie-off of 0 for no output) Field values (Others are reserved): 5'b00000 - MCASP0 AHCLKR Output 5'b00001 - MCASP1 AHCLKR Output 5'b00010 - MCASP2 AHCLKR Output 5'b00011 - MCASP3 AHCLKR Output 5'b00100 - MCASP4 AHCLKR Output 5'b01100 - MCASP0 AHCLKX Output 5'b01101 - MCASP1 AHCLKX Output 5'b01110 - MCASP2 AHCLKX Output 5'b01111 - MCASP3 AHCLKX Output 5'b10000 - MCASP4 AHCLKX Output 5'b11000 - ATCLK0 5'b11001 - ATCLK1 5'b11010 - ATCLK2 5'b11011 - ATCLK3 5'b11100 - MAIN_PLL4_HSDIV2_CLKOUT 5'b11101 - 0 5'b11110 - 0 5'b11111 - 0
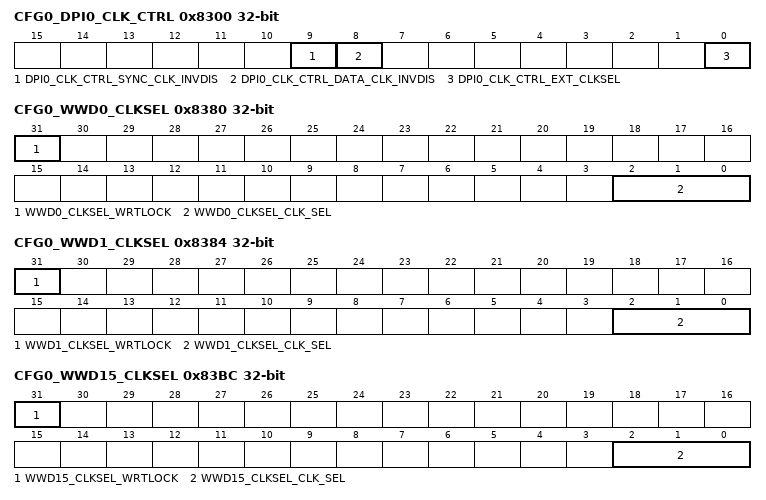
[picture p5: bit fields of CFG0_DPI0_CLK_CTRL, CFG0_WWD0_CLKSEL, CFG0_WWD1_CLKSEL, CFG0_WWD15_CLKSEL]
0x8300 CFG0_DPI0_CLK_CTRL — Selects the clock source for the DPI0 video output
  [9] DPI0_CLK_CTRL_SYNC_CLK_INVDIS — Clock edge select for DPI0 sync outputs 0 - HSYNC and VSYNC are driven on the falling edge of clk 1 - HSYNC and VSYNC are driven on the rising edge of clkNote that this value should align with the programmed value of the DSS POL_FREQ.RF bitfield.
  [8] DPI0_CLK_CTRL_DATA_CLK_INVDIS — Clock edge select for DPI0 data outputs 0 - DATA and DE are driven on the falling edge of clk 1 - DATA and DE are driven on the rising edge of clkNote that this value should align with the programmed value of the DSS POL_FREQ.IPC bitfield.
  [0] DPI0_CLK_CTRL_EXT_CLKSEL — Selects whether to use DSS PLL3 or an external pin as a DPI clock source. (See the J7AM Clock Specification for more details.) 0 - Use internal clock : MAIN_PLL19_HSDIV0_CLKOUT 1 - Use external clock : VOUT0_EXTPCLKIN
0x8310 CFG0_DPHY0_CLKSEL — Selects the clock source for the DSI0 transmit PHY
  [1:0] DPHY0_CLKSEL_REF_CLK_SEL — DPHY reference clock source 2'b00 - HFOSC0_CLKOUT 2'b01 - HFOSC1_CLKOUT 2'b10 - MAIN_PLL3_HSDIV4_CLKOUT 2'b11 - MAIN_PLL2_HSDIV4_CLKOUT
0x8314 CFG0_DPHY1_CLKSEL — Selects the clock source for the DSI1 transmit PHY
  [1:0] DPHY1_CLKSEL_REF_CLK_SEL — DPHY reference clock source 2'b00 - HFOSC0_CLKOUT 2'b01 - HFOSC1_CLKOUT 2'b10 - MAIN_PLL3_HSDIV4_CLKOUT 2'b11 - MAIN_PLL2_HSDIV4_CLKOUT
0x8324 CFG0_DSS_DISPC0_CLKSEL1 — Selects the clock source for DPI Lane 1 of Display Controller Instance 0
  [1:0] DSS_DISPC0_CLKSEL1_DPI1_PCLK — DPI lane 1 pixel clock source Field values (Others are reserved): 2'b00 - MAIN_PLL17_HSDIV0_CLKOUT 2'b01 - MAIN_PLL19_HSDIV0_CLKOUT_EXTPCLKIN 2'b10 - MAIN_PLL19_HSDIV0_CLKOUT_EXTPCLKIN 2'b11 - MAIN_PLL16_HSDIV0_CLKOUT
0x8328 CFG0_DSS_DISPC0_CLKSEL2 — Selects the clock source for DPI Lane 2 of Display Controller Instance 0
  [0] DSS_DISPC0_CLKSEL2_DPI2_PCLK — DPI lane 2 pixel clock source Field values (Others are reserved): 1'b0 - MAIN_PLL16_HSDIV0_CLKOUT 1'b1 - MAIN_PLL17_HSDIV0_CLKOUT
0x832C CFG0_DSS_DISPC0_CLKSEL3 — Can also override the DPI Lane 0 and DPI Lane 2 clock source for certain values.
  [2:0] DSS_DISPC0_CLKSEL3_DPI3_PCLK — DPI lane 3 pixel clock sourceNote that values of 3'b1x1 also change the DPI lane 0 pixel clock source and values of 3'b11x change the DPI lane 2 pixel clock source Field values (Others are reserved): 3'b000 - MAIN_PLL16_HSDIV1_CLKOUT 3'b001 - MAIN_PLL17_HSDIV1_CLKOUT 3'b010 - MAIN_PLL17_HSDIV1_CLKOUT 3'b011 - MAIN_PLL19_HSDIV0_CLKOUT_EXTPCLKIN 3'b100 - MAIN_PLL19_HSDIV0_CLKOUT_EXTPCLKIN 3'b101 - MAIN_PLL19_HSDIV0_CLKOUT_EXTPCLKIN and dpi0_pclk = dpi1_pclk 3'b110 - MAIN_PLL19_HSDIV0_CLKOUT_EXTPCLKIN and dpi2_pclk = MAIN_PLL19_HSDIV0_CLKOUT_EXTPCLKIN 3'b111 - MAIN_PLL19_HSDIV0_CLKOUT_EXTPCLKIN and dpi0_pclk = dpi1_pclk and dpi2_pclk = MAIN_PLL19_HSDIV0_CLKOUT_EXTPCLKIN
0x8350 CFG0_EDP0_CLK_CTRL — Controls clock operation for Embedded Display Port 0
  [8] EDP0_CLK_CTRL_DSI_CLK_DYN_SWTCH_DIS — EDP0 DSI clock dynamic switch disable.This bit controls whether the EDP source clock is dynamically switched (to MAIN_PLL2_HSDIV7_CLKOUT) on a warm reset event. (See PLL Bypass Logic during Main WarmReset details in the Reset MicroArch Specification). This bit only applies if eDP reset isolation is enabled. 0 - Dynamic switching on warm reset is enabled 1 - Dynamic switching on warm reset is disabled
0x8380 CFG0_WWD0_CLKSEL — ARM MPU Cluster 0 Core 0 Windowed watchdog timer functional clock selection control
  [31] WWD0_CLKSEL_WRTLOCK — When set, locks WWD0_CLKSEL from further writes until the next module reset.
  [2:0] WWD0_CLKSEL_CLK_SEL — Windowed watchdog timer functional clock input select mux control Field values (Others are reserved): 3'b000 - HFOSC0_CLKOUT 3'b001 - LFXOSC_CLKOUT 3'b010 - CLK_12M_RC 3'b011 - CLK_32K 3'b100 - HFOSC1_CLKOUT 3'b101 - reserved (HFOSC1_CLKOUT) 3'b110 - reserved (HFOSC1_CLKOUT) 3'b111 - reserved (HFOSC1_CLKOUT)
0x8384 CFG0_WWD1_CLKSEL — ARM MPU Cluster 0 Core 1 Windowed watchdog timer functional clock selection control
  [31] WWD1_CLKSEL_WRTLOCK — When set, locks WWD1_CLKSEL from further writes until the next module reset.
  [2:0] WWD1_CLKSEL_CLK_SEL — Windowed watchdog timer functional clock input select mux control Field values (Others are reserved): 3'b000 - HFOSC0_CLKOUT 3'b001 - LFXOSC_CLKOUT 3'b010 - CLK_12M_RC 3'b011 - CLK_32K 3'b100 - HFOSC1_CLKOUT 3'b101 - reserved (HFOSC1_CLKOUT) 3'b110 - reserved (HFOSC1_CLKOUT) 3'b111 - reserved (HFOSC1_CLKOUT)
0x83BC CFG0_WWD15_CLKSEL — GPU Windowed watchdog timer functional clock selection control
  [31] WWD15_CLKSEL_WRTLOCK — When set, locks WWD15_CLKSEL from further writes until the next module reset.
  [2:0] WWD15_CLKSEL_CLK_SEL — Windowed watchdog timer functional clock input select mux control Field values (Others are reserved): 3'b000 - HFOSC0_CLKOUT 3'b001 - LFXOSC_CLKOUT 3'b010 - CLK_12M_RC 3'b011 - CLK_32K 3'b100 - HFOSC1_CLKOUT 3'b101 - reserved (HFOSC1_CLKOUT) 3'b110 - reserved (HFOSC1_CLKOUT) 3'b111 - reserved (HFOSC1_CLKOUT)
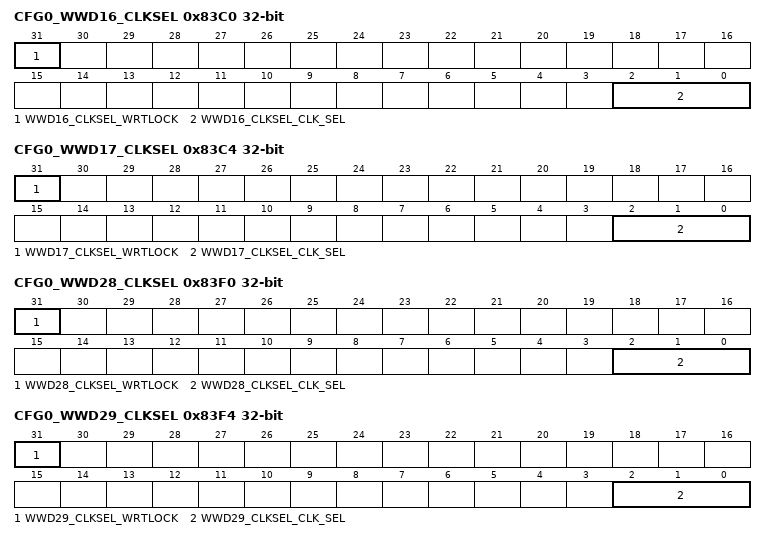
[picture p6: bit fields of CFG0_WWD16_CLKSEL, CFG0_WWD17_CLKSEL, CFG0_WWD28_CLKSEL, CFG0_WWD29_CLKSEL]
0x83C0 CFG0_WWD16_CLKSEL — C71x Core 0 Windowed watchdog timer functional clock selection control
  [31] WWD16_CLKSEL_WRTLOCK — When set, locks WWD16_CLKSEL from further writes until the next module reset.
  [2:0] WWD16_CLKSEL_CLK_SEL — Windowed watchdog timer functional clock input select mux control Field values (Others are reserved): 3'b000 - HFOSC0_CLKOUT 3'b001 - LFXOSC_CLKOUT 3'b010 - CLK_12M_RC 3'b011 - CLK_32K 3'b100 - HFOSC1_CLKOUT 3'b101 - reserved (HFOSC1_CLKOUT) 3'b110 - reserved (HFOSC1_CLKOUT) 3'b111 - reserved (HFOSC1_CLKOUT)
0x83C4 CFG0_WWD17_CLKSEL — C71x Core 1 Windowed watchdog timer functional clock selection control
  [31] WWD17_CLKSEL_WRTLOCK — When set, locks WWD17_CLKSEL from further writes until the next module reset.
  [2:0] WWD17_CLKSEL_CLK_SEL — Windowed watchdog timer functional clock input select mux control Field values (Others are reserved): 3'b000 - HFOSC0_CLKOUT 3'b001 - LFXOSC_CLKOUT 3'b010 - CLK_12M_RC 3'b011 - CLK_32K 3'b100 - HFOSC1_CLKOUT 3'b101 - reserved (HFOSC1_CLKOUT) 3'b110 - reserved (HFOSC1_CLKOUT) 3'b111 - reserved (HFOSC1_CLKOUT)
0x83F0 CFG0_WWD28_CLKSEL — Main R5 Clstr0 Core0 Windowed watchdog timer functional clock selection control.
  [31] WWD28_CLKSEL_WRTLOCK — When set, locks WWD28_CLKSEL from further writes until the next module reset.
  [2:0] WWD28_CLKSEL_CLK_SEL — Windowed watchdog timer functional clock input select mux controlThese bits are warm reset isolated to preserve R5 RTI clock selection. Field values (Others are reserved): 3'b000 - HFOSC0_CLKOUT 3'b001 - LFXOSC_CLKOUT 3'b010 - CLK_12M_RC 3'b011 - CLK_32K 3'b100 - HFOSC1_CLKOUT 3'b101 - reserved (HFOSC1_CLKOUT) 3'b110 - reserved (HFOSC1_CLKOUT) 3'b111 - reserved (HFOSC1_CLKOUT)
0x83F4 CFG0_WWD29_CLKSEL — Main R5 Clstr0 Core1 Windowed watchdog timer functional clock selection control.
  [31] WWD29_CLKSEL_WRTLOCK — When set, locks WWD29_CLKSEL from further writes until the next module reset.
  [2:0] WWD29_CLKSEL_CLK_SEL — Windowed watchdog timer functional clock input select mux controlThese bits are warm reset isolated to preserve R5 RTI clock selection. Field values (Others are reserved): 3'b000 - HFOSC0_CLKOUT 3'b001 - LFXOSC_CLKOUT 3'b010 - CLK_12M_RC 3'b011 - CLK_32K 3'b100 - HFOSC1_CLKOUT 3'b101 - reserved (HFOSC1_CLKOUT) 3'b110 - reserved (HFOSC1_CLKOUT) 3'b111 - reserved (HFOSC1_CLKOUT)
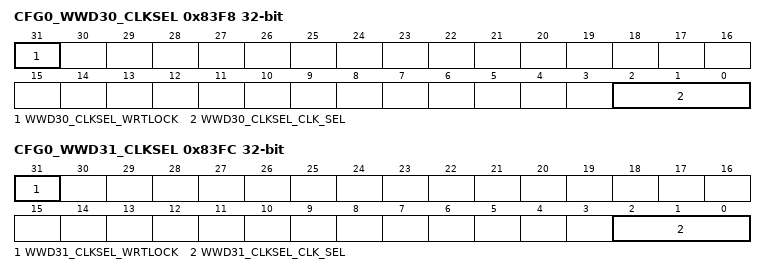
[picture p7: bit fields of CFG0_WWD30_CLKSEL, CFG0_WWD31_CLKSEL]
0x83F8 CFG0_WWD30_CLKSEL — Main R5 Clstr1 Core0 Windowed watchdog timer functional clock selection control.
  [31] WWD30_CLKSEL_WRTLOCK — When set, locks WWD30_CLKSEL from further writes until the next module reset.
  [2:0] WWD30_CLKSEL_CLK_SEL — Windowed watchdog timer functional clock input select mux controlThese bits are warm reset isolated to preserve R5 RTI clock selection. Field values (Others are reserved): 3'b000 - HFOSC0_CLKOUT 3'b001 - LFXOSC_CLKOUT 3'b010 - CLK_12M_RC 3'b011 - CLK_32K 3'b100 - HFOSC1_CLKOUT 3'b101 - reserved (HFOSC1_CLKOUT) 3'b110 - reserved (HFOSC1_CLKOUT) 3'b111 - reserved (HFOSC1_CLKOUT)
0x83FC CFG0_WWD31_CLKSEL — Main R5 Clstr1 Core1 Windowed watchdog timer functional clock selection control.
  [31] WWD31_CLKSEL_WRTLOCK — When set, locks WWD31_CLKSEL from further writes until the next module reset.
  [2:0] WWD31_CLKSEL_CLK_SEL — Windowed watchdog timer functional clock input select mux controlThese bits are warm reset isolated to preserve R5 RTI clock selection. Field values (Others are reserved): 3'b000 - HFOSC0_CLKOUT 3'b001 - LFXOSC_CLKOUT 3'b010 - CLK_12M_RC 3'b011 - CLK_32K 3'b100 - HFOSC1_CLKOUT 3'b101 - reserved (HFOSC1_CLKOUT) 3'b110 - reserved (HFOSC1_CLKOUT) 3'b111 - reserved (HFOSC1_CLKOUT)
0x8400 CFG0_SERDES0_CLKSEL — Selects the clock source for Serdes0.
  [1:0] SERDES0_CLKSEL_CORE_REFCLK_SEL — Selects the source for the core_refclk input Field values (Others are reserved): 2'b00 - HFOSC0_CLKOUT 2'b01 - HFOSC1_CLKOUT 2'b10 - MAIN_PLL3_HSDIV4_CLKOUT 2'b11 - MAIN_PLL2_HSDIV4_CLKOUT
{0x8480+4i} CFG0_MCAN{i}_CLKSEL (i=0..17) — Controls the functional clock source MCAN{i}
  [1:0] MCAN{i}_CLKSEL_CLK_SEL — MAIN MCAN_CLK selection 2'b00 - MAIN_PLL0_HSDIV4_CLKOUT 2'b01 - MCU_EXT_REFCLK0 (pin) 2'b10 - HFOSC1_CLKOUT 2'b11 - HFOSC0_CLKOUT
